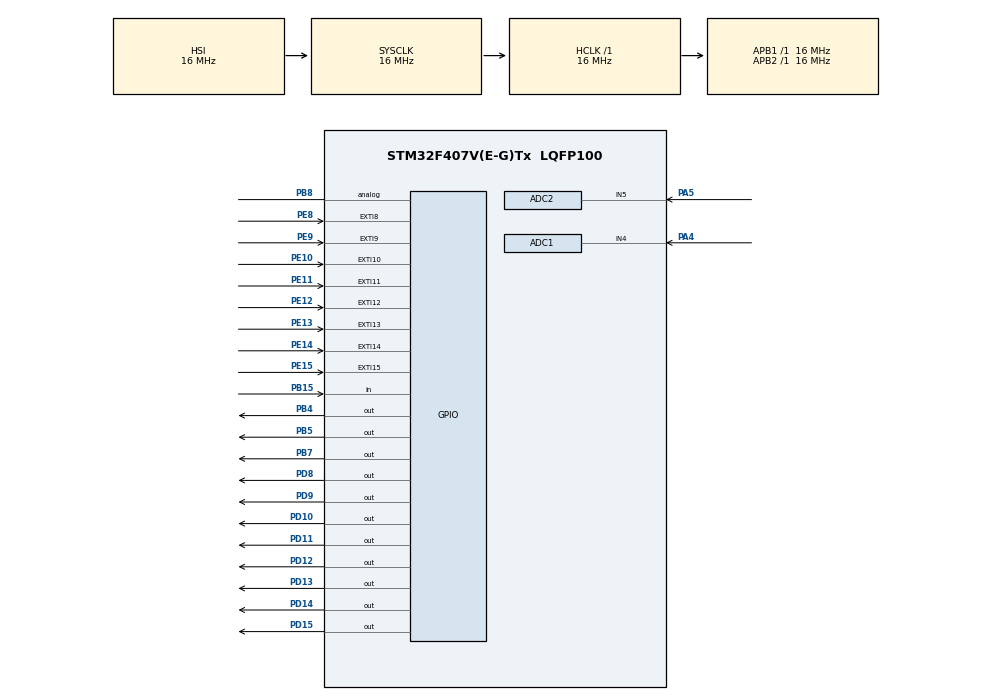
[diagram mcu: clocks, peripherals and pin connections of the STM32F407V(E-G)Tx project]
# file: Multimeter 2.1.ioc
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Mcu.Family=STM32F4
RCC.CortexFreq_Value=16000000
ADC1.Rank-0\#ChannelRegularConversion=1
ADC2.Channel-0\#ChannelRegularConversion=ADC_CHANNEL_5
PD9.Signal=GPIO_Output
PB15.Signal=GPIO_Input
ProjectManager.StackSize=0x400
PD10.Signal=GPIO_Output
PD13.Signal=GPIO_Output
ProjectManager.TargetToolchain=MDK-ARM V5
PD8.Signal=GPIO_Output
PE11.Signal=GPXTI11
RCC.LSE_VALUE=32768
RCC.AHBFreq_Value=16000000
NVIC.EXTI15_10_IRQn=true\:0\:0\:false\:false\:true\:true\:true
PA5.Signal=ADCx_IN5
ADC1.Channel-0\#ChannelRegularConversion=ADC_CHANNEL_4
RCC.HSE_VALUE=25000000
board=custom
RCC.VCOOutputFreq_Value=192000000
RCC.APB2Freq_Value=16000000
PE14.Signal=GPXTI14
PE13.Signal=GPXTI13
PE15.Signal=GPXTI15
PE8.Signal=GPXTI8
PE9.Signal=GPXTI9
SH.ADCx_IN4.0=ADC1_IN4,IN4
PB7.Signal=GPIO_Output
PE10.Signal=GPXTI10
Mcu.Name=STM32F407V(E-G)Tx
PE12.Signal=GPXTI12
ADC1.SamplingTime-0\#ChannelRegularConversion=ADC_SAMPLETIME_3CYCLES
PD14.Signal=GPIO_Output
PA4.Signal=ADCx_IN4
RCC.SYSCLKFreq_VALUE=16000000
Mcu.Package=LQFP100
PB5.Signal=GPIO_Output
ADC1.master=1
ADC2.NbrOfConversionFlag=1
PD11.Signal=GPIO_Output
PD12.Signal=GPIO_Output
NVIC.EXTI9_5_IRQn=true\:0\:0\:false\:false\:true\:true\:true
ProjectManager.HeapSize=0x200
ADC2.SamplingTime-0\#ChannelRegularConversion=ADC_SAMPLETIME_3CYCLES
RCC.HSI_VALUE=16000000
SH.ADCx_IN5.0=ADC2_IN5,IN5
NVIC.PriorityGroup=NVIC_PRIORITYGROUP_4
ADC1.NbrOfConversionFlag=1
PB8.Signal=GPIO_Analog
ADC2.Rank-0\#ChannelRegularConversion=1
RCC.APB1Freq_Value=16000000
PD15.Signal=GPIO_Output
PB4.Signal=GPIO_Output

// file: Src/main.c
/* USER CODE BEGIN Header */
/**
  ******************************************************************************
  * @file           : main.c
  * @brief          : Main program body
  ******************************************************************************
  * @attention
  *
  * <h2><center>&copy; Copyright (c) 2020 STMicroelectronics.
  * All rights reserved.</center></h2>
  *
  * This software component is licensed by ST under BSD 3-Clause license,
  * the "License"; You may not use this file except in compliance with the
  * License. You may obtain a copy of the License at:
  *                        opensource.org/licenses/BSD-3-Clause
  *
  ******************************************************************************
  */
/* USER CODE END Header */

#include "main.h"

ADC_HandleTypeDef hadc1;
ADC_HandleTypeDef hadc2;

void SystemClock_Config(void);
static void MX_GPIO_Init(void);
static void MX_ADC1_Init(void);
static void MX_ADC2_Init(void);

int main(void)
{

  /* MCU Configuration--------------------------------------------------------*/

  /* Reset of all peripherals, Initializes the Flash interface and the Systick. */
  HAL_Init();

  /* Configure the system clock */
  SystemClock_Config();

  /* Initialize all configured peripherals */
  MX_GPIO_Init();
  MX_ADC1_Init();
  MX_ADC2_Init();

  /* Infinite loop */
  /* USER CODE BEGIN WHILE */
  while (1)
  {

    //Display main menu

    /* USER CODE END WHILE */

  }
}

void SystemClock_Config(void)
{
  RCC_OscInitTypeDef RCC_OscInitStruct = {0};
  RCC_ClkInitTypeDef RCC_ClkInitStruct = {0};

  /** Configure the main internal regulator output voltage
  */
  __HAL_RCC_PWR_CLK_ENABLE();
  __HAL_PWR_VOLTAGESCALING_CONFIG(PWR_REGULATOR_VOLTAGE_SCALE1);
  /** Initializes the CPU, AHB and APB busses clocks
  */
  RCC_OscInitStruct.OscillatorType = RCC_OSCILLATORTYPE_HSI;
  RCC_OscInitStruct.HSIState = RCC_HSI_ON;
  RCC_OscInitStruct.HSICalibrationValue = RCC_HSICALIBRATION_DEFAULT;
  RCC_OscInitStruct.PLL.PLLState = RCC_PLL_NONE;
  if (HAL_RCC_OscConfig(&RCC_OscInitStruct) != HAL_OK)
  {
    Error_Handler();
  }
  /** Initializes the CPU, AHB and APB busses clocks
  */
  RCC_ClkInitStruct.ClockType = RCC_CLOCKTYPE_HCLK|RCC_CLOCKTYPE_SYSCLK
                              |RCC_CLOCKTYPE_PCLK1|RCC_CLOCKTYPE_PCLK2;
  RCC_ClkInitStruct.SYSCLKSource = RCC_SYSCLKSOURCE_HSI;
  RCC_ClkInitStruct.AHBCLKDivider = RCC_SYSCLK_DIV1;
  RCC_ClkInitStruct.APB1CLKDivider = RCC_HCLK_DIV1;
  RCC_ClkInitStruct.APB2CLKDivider = RCC_HCLK_DIV1;

  if (HAL_RCC_ClockConfig(&RCC_ClkInitStruct, FLASH_LATENCY_0) != HAL_OK)
  {
    Error_Handler();
  }
}

static void MX_ADC1_Init(void)
{

  ADC_ChannelConfTypeDef sConfig = {0};

  /** Configure the global features of the ADC (Clock, Resolution, Data Alignment and number of conversion)
  */
  hadc1.Instance = ADC1;
  hadc1.Init.ClockPrescaler = ADC_CLOCK_SYNC_PCLK_DIV2;
  hadc1.Init.Resolution = ADC_RESOLUTION_12B;
  hadc1.Init.ScanConvMode = DISABLE;
  hadc1.Init.ContinuousConvMode = DISABLE;
  hadc1.Init.DiscontinuousConvMode = DISABLE;
  hadc1.Init.ExternalTrigConvEdge = ADC_EXTERNALTRIGCONVEDGE_NONE;
  hadc1.Init.ExternalTrigConv = ADC_SOFTWARE_START;
  hadc1.Init.DataAlign = ADC_DATAALIGN_RIGHT;
  hadc1.Init.NbrOfConversion = 1;
  hadc1.Init.DMAContinuousRequests = DISABLE;
  hadc1.Init.EOCSelection = ADC_EOC_SINGLE_CONV;
  if (HAL_ADC_Init(&hadc1) != HAL_OK)
  {
    Error_Handler();
  }
  /** Configure for the selected ADC regular channel its corresponding rank in the sequencer and its sample time.
  */
  sConfig.Channel = ADC_CHANNEL_4;
  sConfig.Rank = 1;
  sConfig.SamplingTime = ADC_SAMPLETIME_3CYCLES;
  if (HAL_ADC_ConfigChannel(&hadc1, &sConfig) != HAL_OK)
  {
    Error_Handler();
  }

}

static void MX_ADC2_Init(void)
{

  ADC_ChannelConfTypeDef sConfig = {0};

  /** Configure the global features of the ADC (Clock, Resolution, Data Alignment and number of conversion)
  */
  hadc2.Instance = ADC2;
  hadc2.Init.ClockPrescaler = ADC_CLOCK_SYNC_PCLK_DIV2;
  hadc2.Init.Resolution = ADC_RESOLUTION_12B;
  hadc2.Init.ScanConvMode = DISABLE;
  hadc2.Init.ContinuousConvMode = DISABLE;
  hadc2.Init.DiscontinuousConvMode = DISABLE;
  hadc2.Init.ExternalTrigConvEdge = ADC_EXTERNALTRIGCONVEDGE_NONE;
  hadc2.Init.ExternalTrigConv = ADC_SOFTWARE_START;
  hadc2.Init.DataAlign = ADC_DATAALIGN_RIGHT;
  hadc2.Init.NbrOfConversion = 1;
  hadc2.Init.DMAContinuousRequests = DISABLE;
  hadc2.Init.EOCSelection = ADC_EOC_SINGLE_CONV;
  if (HAL_ADC_Init(&hadc2) != HAL_OK)
  {
    Error_Handler();
  }
  /** Configure for the selected ADC regular channel its corresponding rank in the sequencer and its sample time.
  */
  sConfig.Channel = ADC_CHANNEL_5;
  sConfig.Rank = 1;
  sConfig.SamplingTime = ADC_SAMPLETIME_3CYCLES;
  if (HAL_ADC_ConfigChannel(&hadc2, &sConfig) != HAL_OK)
  {
    Error_Handler();
  }

}

static void MX_GPIO_Init(void)
{
  GPIO_InitTypeDef GPIO_InitStruct = {0};

  /* GPIO Ports Clock Enable */
  __HAL_RCC_GPIOA_CLK_ENABLE();
  __HAL_RCC_GPIOE_CLK_ENABLE();
  __HAL_RCC_GPIOB_CLK_ENABLE();
  __HAL_RCC_GPIOD_CLK_ENABLE();

  /*Configure GPIO pin Output Level */
  HAL_GPIO_WritePin(GPIOD, GPIO_PIN_8|GPIO_PIN_9|GPIO_PIN_10|GPIO_PIN_11
                          |GPIO_PIN_12|GPIO_PIN_13|GPIO_PIN_14|GPIO_PIN_15, GPIO_PIN_RESET);

  /*Configure GPIO pin Output Level */
  HAL_GPIO_WritePin(GPIOB, GPIO_PIN_4|GPIO_PIN_5|GPIO_PIN_7, GPIO_PIN_RESET);

  /*Configure GPIO pins : PE8 PE9 PE10 PE11
                           PE12 PE13 PE14 PE15 */
  GPIO_InitStruct.Pin = GPIO_PIN_8|GPIO_PIN_9|GPIO_PIN_10|GPIO_PIN_11
                          |GPIO_PIN_12|GPIO_PIN_13|GPIO_PIN_14|GPIO_PIN_15;
  GPIO_InitStruct.Mode = GPIO_MODE_IT_RISING;
  GPIO_InitStruct.Pull = GPIO_NOPULL;
  HAL_GPIO_Init(GPIOE, &GPIO_InitStruct);

  /*Configure GPIO pin : PB15 */
  GPIO_InitStruct.Pin = GPIO_PIN_15;
  GPIO_InitStruct.Mode = GPIO_MODE_INPUT;
  GPIO_InitStruct.Pull = GPIO_NOPULL;
  HAL_GPIO_Init(GPIOB, &GPIO_InitStruct);

  /*Configure GPIO pins : PD8 PD9 PD10 PD11
                           PD12 PD13 PD14 PD15 */
  GPIO_InitStruct.Pin = GPIO_PIN_8|GPIO_PIN_9|GPIO_PIN_10|GPIO_PIN_11
                          |GPIO_PIN_12|GPIO_PIN_13|GPIO_PIN_14|GPIO_PIN_15;
  GPIO_InitStruct.Mode = GPIO_MODE_OUTPUT_PP;
  GPIO_InitStruct.Pull = GPIO_NOPULL;
  GPIO_InitStruct.Speed = GPIO_SPEED_FREQ_LOW;
  HAL_GPIO_Init(GPIOD, &GPIO_InitStruct);

  /*Configure GPIO pins : PB4 PB5 PB7 */
  GPIO_InitStruct.Pin = GPIO_PIN_4|GPIO_PIN_5|GPIO_PIN_7;
  GPIO_InitStruct.Mode = GPIO_MODE_OUTPUT_PP;
  GPIO_InitStruct.Pull = GPIO_NOPULL;
  GPIO_InitStruct.Speed = GPIO_SPEED_FREQ_LOW;
  HAL_GPIO_Init(GPIOB, &GPIO_InitStruct);

  /*Configure GPIO pin : PB8 */
  GPIO_InitStruct.Pin = GPIO_PIN_8;
  GPIO_InitStruct.Mode = GPIO_MODE_ANALOG;
  GPIO_InitStruct.Pull = GPIO_NOPULL;
  HAL_GPIO_Init(GPIOB, &GPIO_InitStruct);

  /* EXTI interrupt init*/
  HAL_NVIC_SetPriority(EXTI9_5_IRQn, 0, 0);
  HAL_NVIC_EnableIRQ(EXTI9_5_IRQn);

  HAL_NVIC_SetPriority(EXTI15_10_IRQn, 0, 0);
  HAL_NVIC_EnableIRQ(EXTI15_10_IRQn);

}

void Error_Handler(void)
{
}

/************************ (C) COPYRIGHT STMicroelectronics *****END OF FILE****/
